# MDR1986VK01 register map
File version: 1.0.2
Registers are 32-bit, read-write, no defined reset value unless marked. A register's access mark holds for its fields unless they carry their own. Offsets are from the block's base; [hi:lo] are bit positions; {n}, {i} and the like mark numbered series; 'fields as' and 'values as' point back to an identical list.

## MDR_MIL0_STD_1553 — MDR_MIL0_STD_1553 description
Base 0x40091000
Same registers: MDR_MIL1_STD_1553 0x40087000
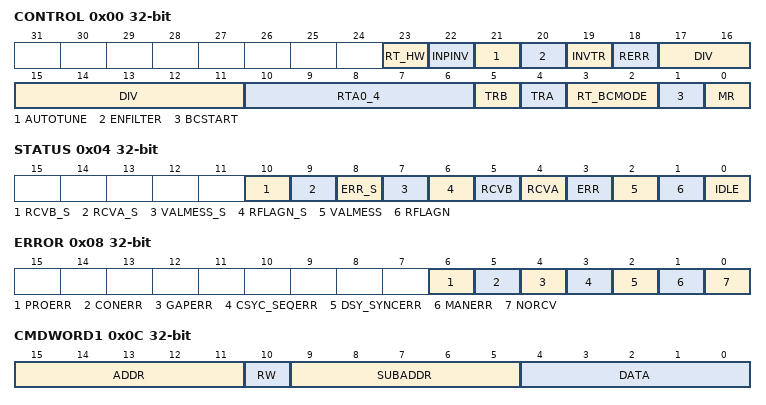
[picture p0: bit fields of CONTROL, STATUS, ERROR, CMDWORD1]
0x00 CONTROL — CONTROL description
  [23] RT_HW — RT_HW description
  [22] INPINV — INPINV description
  [21] AUTOTUNE — AUTOTUNE description
  [20] ENFILTER — ENFILTER description
  [19] INVTR — INVTR description
  [18] RERR — RERR description
  [17:11] DIV — DIV description
  [10:6] RTA0_4 — RTA0_4 description
  [5] TRB — TRB description
  [4] TRA — TRA description
  [3:2] RT_BCMODE — RT_BCMODE description
  [1] BCSTART — BCSTART description
  [0] MR — MR description
0x04 STATUS — STATUS description
  [10] RCVB_S — RCVB_S description
  [9] RCVA_S — RCVA_S description
  [8] ERR_S — ERR_S description
  [7] VALMESS_S — VALMESS_S description
  [6] RFLAGN_S — RFLAGN_S description
  [5] RCVB — RCVB description
  [4] RCVA — RCVA description
  [3] ERR — ERR description
  [2] VALMESS — VALMESS description
  [1] RFLAGN — RFLAGN description
  [0] IDLE — IDLE description
0x08 ERROR — ERROR description
  [6] PROERR — PROERR description
  [5] CONERR — CONERR description
  [4] GAPERR — GAPERR description
  [3] CSYC_SEQERR — CSYC_SEQERR description
  [2] DSY_SYNCERR — DSY_SYNCERR description
  [1] MANERR — MANERR description
  [0] NORCV — NORCV description
0x0C CMDWORD1 — CMDWORD1 description
  [15:11] ADDR — ADDR description
  [10] RW — RW description
  [9:5] SUBADDR — SUBADDR description
  [4:0] DATA — DATA description
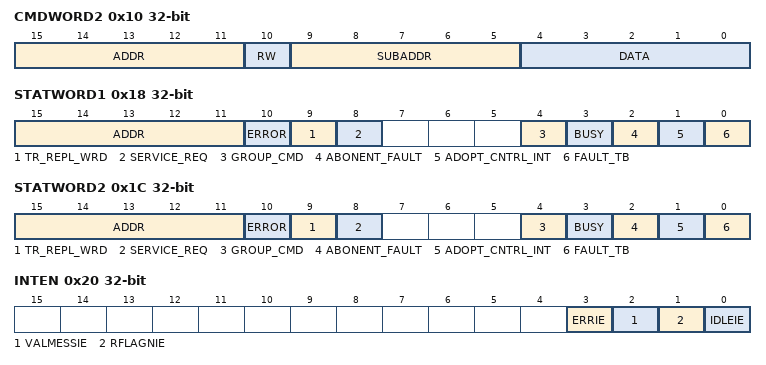
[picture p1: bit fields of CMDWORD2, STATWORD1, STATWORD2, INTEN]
0x10 CMDWORD2 — CMDWORD2 description
  fields as CMDWORD1
0x14 MODEDATA — MODEDATA description
  [15:0] MODEDATA
0x18 STATWORD1 — STATWORD1 description
  [15:11] ADDR — ADDR description
  [10] ERROR — ERROR description
  [9] TR_REPL_WRD — TR_REPL_WRD description
  [8] SERVICE_REQ — SERVICE_REQ description
  [4] GROUP_CMD — GROUP_CMD description
  [3] BUSY — BUSY description
  [2] ABONENT_FAULT — ABONENT_FAULT description
  [1] ADOPT_CNTRL_INT — ADOPT_CNTRL_INT description
  [0] FAULT_TB — FAULT_TB description
0x1C STATWORD2 — STATWORD2 description
  fields as STATWORD1
0x20 INTEN — INTEN description
  [3] ERRIE — ERRIE description
  [2] VALMESSIE — VALMESSIE description
  [1] RFLAGNIE — RFLAGNIE description
  [0] IDLEIE — IDLEIE description
0x24 MSG — MSG description
  [13:0] CODE — CODE description

## MDR_TIMER0 — MDR_TIMER0 description
Base 0x40094000
Same registers: MDR_TIMER1 0x40095000, MDR_TIMER2 0x40096000, MDR_TIMER3 0x40097000
0x00 CNT — CNT description
0x04 PSG — PSG description
  [15:0] PSG
0x08 ARR — ARR description
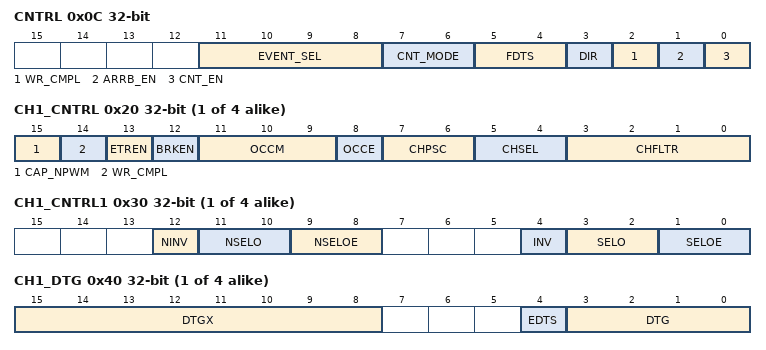
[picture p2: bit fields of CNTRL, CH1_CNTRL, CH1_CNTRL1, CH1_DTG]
0x0C CNTRL — CNTRL description
  [11:8] EVENT_SEL — EVENT_SEL description
  [7:6] CNT_MODE — CNT_MODE description
  [5:4] FDTS — FDTS description
  [3] DIR — DIR description
  [2] WR_CMPL — WR_CMPL description
  [1] ARRB_EN — ARRB_EN description
  [0] CNT_EN — CNT_EN description
{0xC+4i} CCR{i} (i=1..4) — CCR{i} description
{0x1C+4i} CH{i}_CNTRL (i=1..4) — CH{i}_CNTRL description
  [15] CAP_NPWM — CAP_NPWM description
  [14] WR_CMPL — WR_CMPL description
  [13] ETREN — ETREN description
  [12] BRKEN — BRKEN description
  [11:9] OCCM — OCCM description
  [8] OCCE — OCCE description
  [7:6] CHPSC — CHPSC description
  [5:4] CHSEL — CHSEL description
  [3:0] CHFLTR — CHFLTR description
{0x2C+4i} CH{i}_CNTRL1 (i=1..4) — CH{i}_CNTRL1 description
  [12] NINV — NINV description
  [11:10] NSELO — NSELO description
  [9:8] NSELOE — NSELOE description
  [4] INV — INV description
  [3:2] SELO — SELO description
  [1:0] SELOE — SELOE description
{0x3C+4i} CH{i}_DTG (i=1..4) — CH{i}_DTG description
  [15:8] DTGX — DTGX description
  [4] EDTS — EDTS description
  [3:0] DTG — DTG description
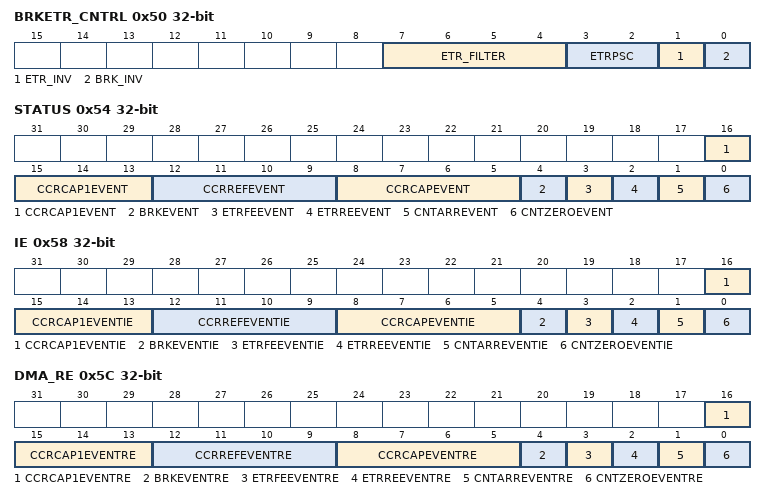
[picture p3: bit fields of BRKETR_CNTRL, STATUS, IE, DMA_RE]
0x50 BRKETR_CNTRL — BRKETR_CNTRL description
  [7:4] ETR_FILTER — ETR_FILTER description
  [3:2] ETRPSC — ETRPSC description
  [1] ETR_INV — ETR_INV description
  [0] BRK_INV — BRK_INV description
0x54 STATUS — STATUS description
  [16:13] CCRCAP1EVENT — CCRCAP1EVENT description
  [12:9] CCRREFEVENT — CCRREFEVENT description
  [8:5] CCRCAPEVENT — CCRCAPEVENT description
  [4] BRKEVENT — BRKEVENT description
  [3] ETRFEEVENT — ETRFEEVENT description
  [2] ETRREEVENT — ETRREEVENT description
  [1] CNTARREVENT — CNTARREVENT description
  [0] CNTZEROEVENT — CNTZEROEVENT description
0x58 IE — IE description
  [16:13] CCRCAP1EVENTIE — CCRCAP1EVENTIE description
  [12:9] CCRREFEVENTIE — CCRREFEVENTIE description
  [8:5] CCRCAPEVENTIE — CCRCAPEVENTIE description
  [4] BRKEVENTIE — BRKEVENTIE description
  [3] ETRFEEVENTIE — ETRFEEVENTIE description
  [2] ETRREEVENTIE — ETRREEVENTIE description
  [1] CNTARREVENTIE — CNTARREVENTIE description
  [0] CNTZEROEVENTIE — CNTZEROEVENTIE description
0x5C DMA_RE — DMA_RE description
  [16:13] CCRCAP1EVENTRE — CCRCAP1EVENTRE description
  [12:9] CCRREFEVENTRE — CCRREFEVENTRE description
  [8:5] CCRCAPEVENTRE — CCRCAPEVENTRE description
  [4] BRKEVENTRE — BRKEVENTRE description
  [3] ETRFEEVENTRE — ETRFEEVENTRE description
  [2] ETRREEVENTRE — ETRREEVENTRE description
  [1] CNTARREVENTRE — CNTARREVENTRE description
  [0] CNTZEROEVENTRE — CNTZEROEVENTRE description
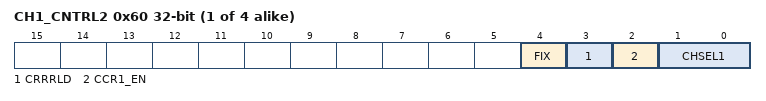
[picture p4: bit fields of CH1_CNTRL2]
{0x5C+4i} CH{i}_CNTRL2 (i=1..4) — CH{i}_CNTRL2 description
  [4] FIX — FIX description
  [3] CRRRLD — CRRRLD description
  [2] CCR1_EN — CCR1_EN description
  [1:0] CHSEL1 — CHSEL1 description
0x70 CCR11 — CCR11 description
0x74 CCR21 — CCR21 description
0x78 CCR31 — CCR31 description
0x7C CCR41 — CCR41 description
{0x7C+4i} DMA_RECH{i} (i=1..4) — DMA_RECH{i} description
